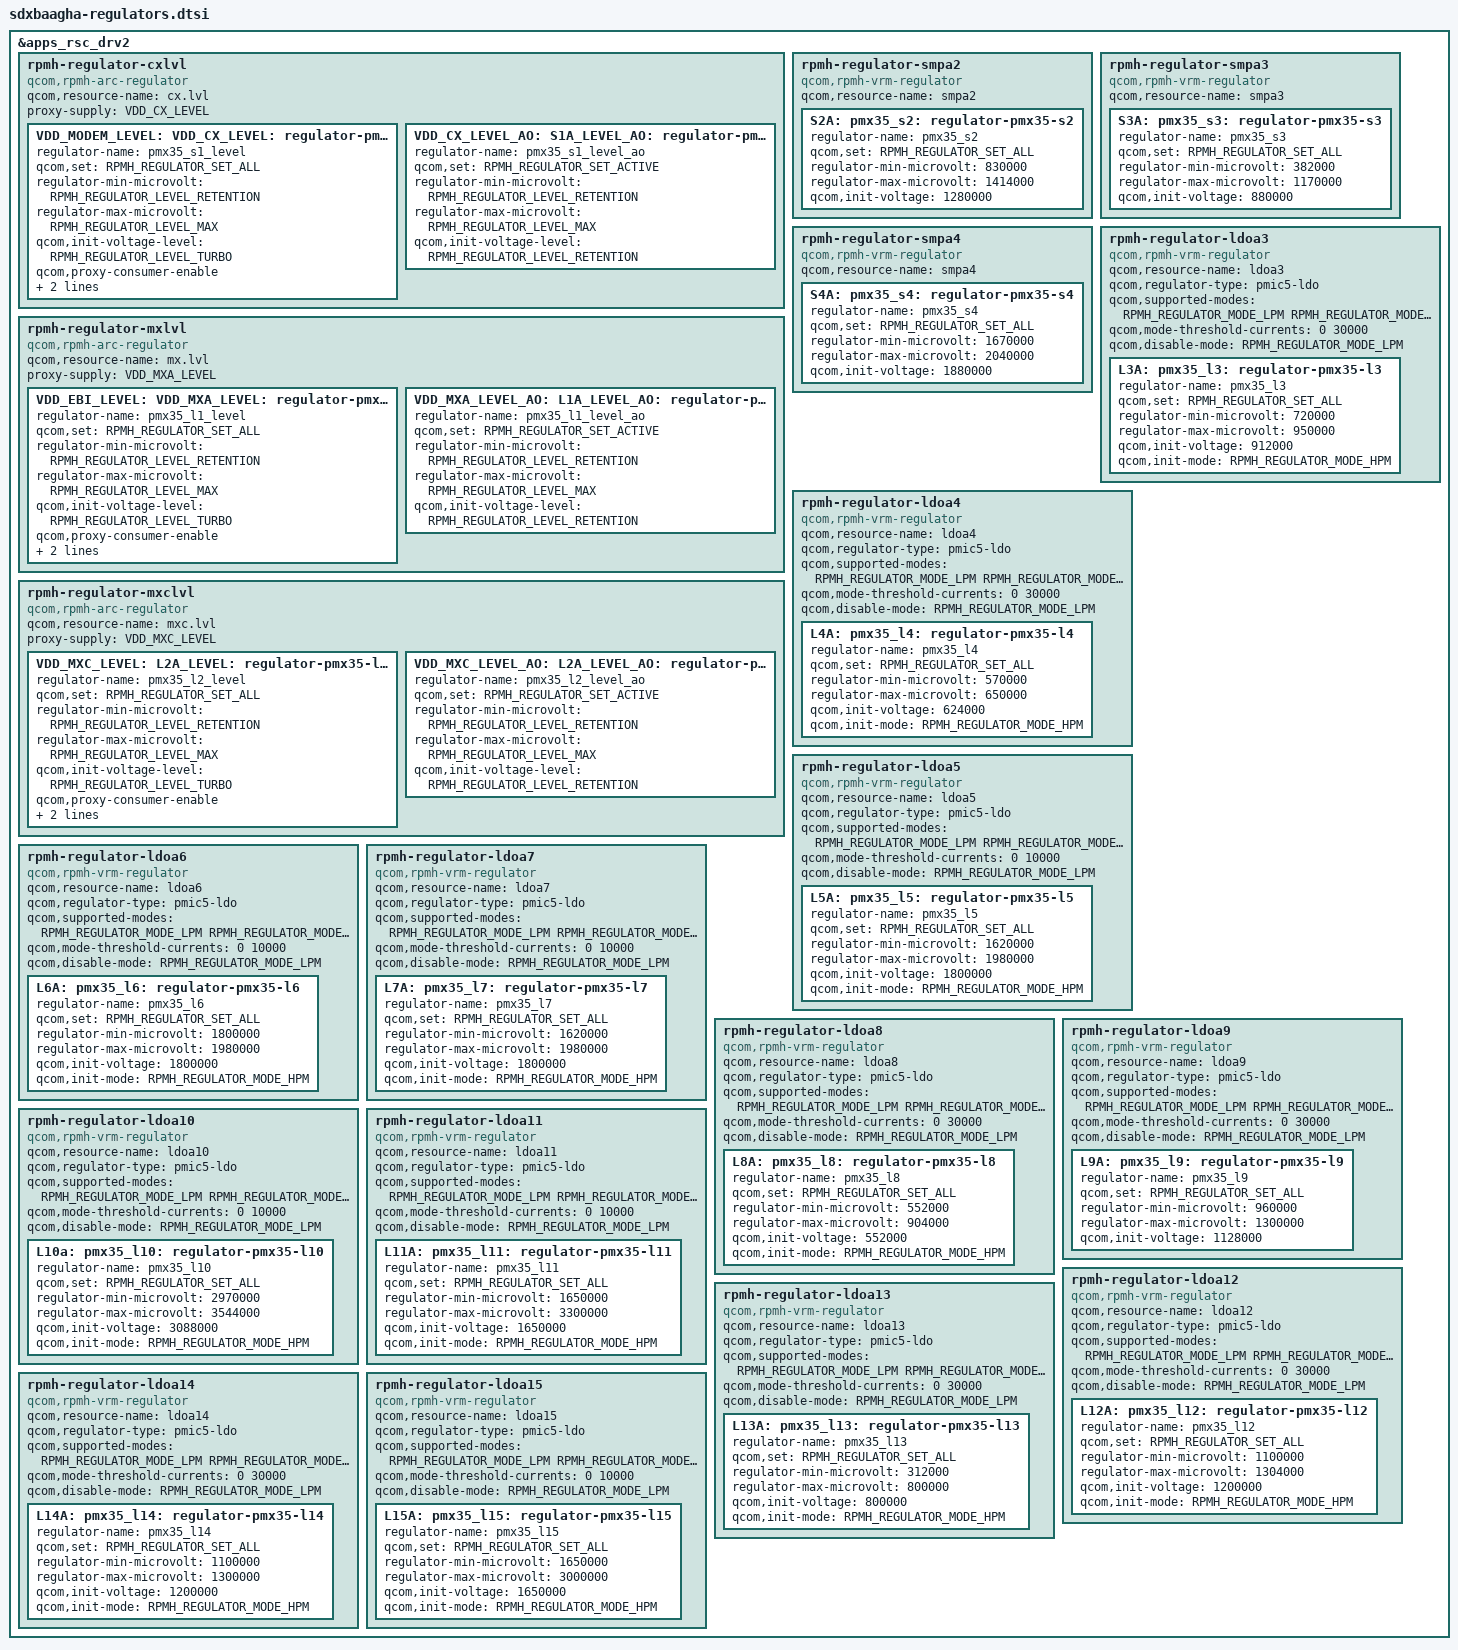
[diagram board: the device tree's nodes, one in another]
#include <dt-bindings/regulator/qcom,rpmh-regulator-levels.h>

&apps_rsc_drv2 {
	rpmh-regulator-cxlvl {
		compatible = "qcom,rpmh-arc-regulator";
		qcom,resource-name = "cx.lvl";
		proxy-supply = <&VDD_CX_LEVEL>;

		VDD_MODEM_LEVEL:
		VDD_CX_LEVEL: S1A_LEVEL:
		pmx35_s1_level: regulator-pmx35-s1-level {
			regulator-name = "pmx35_s1_level";
			qcom,set = <RPMH_REGULATOR_SET_ALL>;
			regulator-min-microvolt =
				<RPMH_REGULATOR_LEVEL_RETENTION>;
			regulator-max-microvolt =
				<RPMH_REGULATOR_LEVEL_MAX>;
			qcom,init-voltage-level =
				<RPMH_REGULATOR_LEVEL_TURBO>;
			qcom,proxy-consumer-enable;
			qcom,proxy-consumer-voltage =
				<RPMH_REGULATOR_LEVEL_TURBO
				 RPMH_REGULATOR_LEVEL_MAX>;

		};

	VDD_CX_LEVEL_AO: S1A_LEVEL_AO:
		pmx35_s1_level_ao: regulator-pmx35-s1-level-ao {
			regulator-name = "pmx35_s1_level_ao";
			qcom,set = <RPMH_REGULATOR_SET_ACTIVE>;
			regulator-min-microvolt =
				<RPMH_REGULATOR_LEVEL_RETENTION>;
			regulator-max-microvolt =
				<RPMH_REGULATOR_LEVEL_MAX>;
			qcom,init-voltage-level =
				<RPMH_REGULATOR_LEVEL_RETENTION>;
		};
	};

	rpmh-regulator-mxlvl {
		compatible = "qcom,rpmh-arc-regulator";
		qcom,resource-name = "mx.lvl";
		proxy-supply = <&VDD_MXA_LEVEL>;

	VDD_EBI_LEVEL: VDD_MXA_LEVEL: L1A_LEVEL:
		pmx35_l1_level: regulator-pmx35-l1-level {
			regulator-name = "pmx35_l1_level";
			qcom,set = <RPMH_REGULATOR_SET_ALL>;
			regulator-min-microvolt =
				<RPMH_REGULATOR_LEVEL_RETENTION>;
			regulator-max-microvolt =
				<RPMH_REGULATOR_LEVEL_MAX>;
			qcom,init-voltage-level =
				<RPMH_REGULATOR_LEVEL_TURBO>;
			qcom,proxy-consumer-enable;
			qcom,proxy-consumer-voltage =
				<RPMH_REGULATOR_LEVEL_TURBO
					RPMH_REGULATOR_LEVEL_MAX>;
		};

		VDD_MXA_LEVEL_AO: L1A_LEVEL_AO:
		pmx35_l1_level_ao: regulator-pmx35-l1-level-ao {
			regulator-name = "pmx35_l1_level_ao";
			qcom,set = <RPMH_REGULATOR_SET_ACTIVE>;
			regulator-min-microvolt =
				<RPMH_REGULATOR_LEVEL_RETENTION>;
			regulator-max-microvolt =
				<RPMH_REGULATOR_LEVEL_MAX>;
			qcom,init-voltage-level =
				<RPMH_REGULATOR_LEVEL_RETENTION>;
		};
	};

	rpmh-regulator-mxclvl {
		compatible = "qcom,rpmh-arc-regulator";
		qcom,resource-name = "mxc.lvl";
		proxy-supply = <&VDD_MXC_LEVEL>;

		VDD_MXC_LEVEL: L2A_LEVEL:
		pmx35_l2_level: regulator-pmx35-l2-level {
			regulator-name = "pmx35_l2_level";
			qcom,set = <RPMH_REGULATOR_SET_ALL>;
			regulator-min-microvolt =
				<RPMH_REGULATOR_LEVEL_RETENTION>;
			regulator-max-microvolt =
				<RPMH_REGULATOR_LEVEL_MAX>;
			qcom,init-voltage-level =
				<RPMH_REGULATOR_LEVEL_TURBO>;
			qcom,proxy-consumer-enable;
			qcom,proxy-consumer-voltage =
				<RPMH_REGULATOR_LEVEL_TURBO
				 RPMH_REGULATOR_LEVEL_MAX>;
		};

		VDD_MXC_LEVEL_AO: L2A_LEVEL_AO:
		pmx35_l2_level_ao: regulator-pmx35-l2-level-ao {
			regulator-name = "pmx35_l2_level_ao";
			qcom,set = <RPMH_REGULATOR_SET_ACTIVE>;
			regulator-min-microvolt =
				<RPMH_REGULATOR_LEVEL_RETENTION>;
			regulator-max-microvolt =
				<RPMH_REGULATOR_LEVEL_MAX>;
			qcom,init-voltage-level =
				<RPMH_REGULATOR_LEVEL_RETENTION>;
		};
	};

	rpmh-regulator-smpa2 {
		compatible = "qcom,rpmh-vrm-regulator";
		qcom,resource-name = "smpa2";

		S2A: pmx35_s2: regulator-pmx35-s2 {
			regulator-name = "pmx35_s2";
			qcom,set = <RPMH_REGULATOR_SET_ALL>;
			regulator-min-microvolt = <830000>;
			regulator-max-microvolt = <1414000>;
			qcom,init-voltage = <1280000>;
		};
	};

	rpmh-regulator-smpa3 {
		compatible = "qcom,rpmh-vrm-regulator";
		qcom,resource-name = "smpa3";

		S3A: pmx35_s3: regulator-pmx35-s3 {
			regulator-name = "pmx35_s3";
			qcom,set = <RPMH_REGULATOR_SET_ALL>;
			regulator-min-microvolt = <382000>;
			regulator-max-microvolt = <1170000>;
			qcom,init-voltage = <880000>;
		};
	};

	rpmh-regulator-smpa4 {
		compatible = "qcom,rpmh-vrm-regulator";
		qcom,resource-name = "smpa4";

		S4A: pmx35_s4: regulator-pmx35-s4 {
			regulator-name = "pmx35_s4";
			qcom,set = <RPMH_REGULATOR_SET_ALL>;
			regulator-min-microvolt = <1670000>;
			regulator-max-microvolt = <2040000>;
			qcom,init-voltage = <1880000>;
		};
	};

	rpmh-regulator-ldoa3 {
		compatible = "qcom,rpmh-vrm-regulator";
		qcom,resource-name = "ldoa3";
		qcom,regulator-type = "pmic5-ldo";
		qcom,supported-modes =
			<RPMH_REGULATOR_MODE_LPM
			 RPMH_REGULATOR_MODE_HPM>;
		qcom,mode-threshold-currents = <0 30000>;
		qcom,disable-mode = <RPMH_REGULATOR_MODE_LPM>;

		L3A: pmx35_l3: regulator-pmx35-l3 {
			regulator-name = "pmx35_l3";
			qcom,set = <RPMH_REGULATOR_SET_ALL>;
			regulator-min-microvolt = <720000>;
			regulator-max-microvolt = <950000>;
			qcom,init-voltage = <912000>;
			qcom,init-mode = <RPMH_REGULATOR_MODE_HPM>;
		};
	};

	rpmh-regulator-ldoa4 {
		compatible = "qcom,rpmh-vrm-regulator";
		qcom,resource-name = "ldoa4";
		qcom,regulator-type = "pmic5-ldo";
		qcom,supported-modes =
			<RPMH_REGULATOR_MODE_LPM
			 RPMH_REGULATOR_MODE_HPM>;
		qcom,mode-threshold-currents = <0 30000>;
		qcom,disable-mode = <RPMH_REGULATOR_MODE_LPM>;

		L4A: pmx35_l4: regulator-pmx35-l4 {
			regulator-name = "pmx35_l4";
			qcom,set = <RPMH_REGULATOR_SET_ALL>;
			regulator-min-microvolt = <570000>;
			regulator-max-microvolt = <650000>;
			qcom,init-voltage = <624000>;
			qcom,init-mode = <RPMH_REGULATOR_MODE_HPM>;
		};
	};

	rpmh-regulator-ldoa5 {
		compatible = "qcom,rpmh-vrm-regulator";
		qcom,resource-name = "ldoa5";
		qcom,regulator-type = "pmic5-ldo";
		qcom,supported-modes =
			<RPMH_REGULATOR_MODE_LPM
			 RPMH_REGULATOR_MODE_HPM>;
		qcom,mode-threshold-currents = <0 10000>;
		qcom,disable-mode = <RPMH_REGULATOR_MODE_LPM>;

		L5A: pmx35_l5: regulator-pmx35-l5 {
			regulator-name = "pmx35_l5";
			qcom,set = <RPMH_REGULATOR_SET_ALL>;
			regulator-min-microvolt = <1620000>;
			regulator-max-microvolt = <1980000>;
			qcom,init-voltage = <1800000>;
			qcom,init-mode = <RPMH_REGULATOR_MODE_HPM>;
		};
	};

	rpmh-regulator-ldoa6 {
		compatible = "qcom,rpmh-vrm-regulator";
		qcom,resource-name = "ldoa6";
		qcom,regulator-type = "pmic5-ldo";
		qcom,supported-modes =
			<RPMH_REGULATOR_MODE_LPM
			 RPMH_REGULATOR_MODE_HPM>;
		qcom,mode-threshold-currents = <0 10000>;
		qcom,disable-mode = <RPMH_REGULATOR_MODE_LPM>;

		L6A: pmx35_l6: regulator-pmx35-l6 {
			regulator-name = "pmx35_l6";
			qcom,set = <RPMH_REGULATOR_SET_ALL>;
			regulator-min-microvolt = <1800000>;
			regulator-max-microvolt = <1980000>;
			qcom,init-voltage = <1800000>;
			qcom,init-mode = <RPMH_REGULATOR_MODE_HPM>;
		};
	};

	rpmh-regulator-ldoa7 {
		compatible = "qcom,rpmh-vrm-regulator";
		qcom,resource-name = "ldoa7";
		qcom,regulator-type = "pmic5-ldo";
		qcom,supported-modes =
			<RPMH_REGULATOR_MODE_LPM
			 RPMH_REGULATOR_MODE_HPM>;
		qcom,mode-threshold-currents = <0 10000>;
		qcom,disable-mode = <RPMH_REGULATOR_MODE_LPM>;

		L7A: pmx35_l7: regulator-pmx35-l7 {
			regulator-name = "pmx35_l7";
			qcom,set = <RPMH_REGULATOR_SET_ALL>;
			regulator-min-microvolt = <1620000>;
			regulator-max-microvolt = <1980000>;
			qcom,init-voltage = <1800000>;
			qcom,init-mode = <RPMH_REGULATOR_MODE_HPM>;
		};
	};

	rpmh-regulator-ldoa8 {
		compatible = "qcom,rpmh-vrm-regulator";
		qcom,resource-name = "ldoa8";
		qcom,regulator-type = "pmic5-ldo";
		qcom,supported-modes =
			<RPMH_REGULATOR_MODE_LPM
			 RPMH_REGULATOR_MODE_HPM>;
		qcom,mode-threshold-currents = <0 30000>;
		qcom,disable-mode = <RPMH_REGULATOR_MODE_LPM>;

		L8A: pmx35_l8: regulator-pmx35-l8 {
			regulator-name = "pmx35_l8";
			qcom,set = <RPMH_REGULATOR_SET_ALL>;
			regulator-min-microvolt = <552000>;
			regulator-max-microvolt = <904000>;
			qcom,init-voltage = <552000>;
			qcom,init-mode = <RPMH_REGULATOR_MODE_HPM>;
		};
	};

	rpmh-regulator-ldoa9 {
		compatible = "qcom,rpmh-vrm-regulator";
		qcom,resource-name = "ldoa9";
		qcom,regulator-type = "pmic5-ldo";
		qcom,supported-modes =
			<RPMH_REGULATOR_MODE_LPM
			 RPMH_REGULATOR_MODE_HPM>;
		qcom,mode-threshold-currents = <0 30000>;
		qcom,disable-mode = <RPMH_REGULATOR_MODE_LPM>;

		L9A: pmx35_l9: regulator-pmx35-l9 {
			regulator-name = "pmx35_l9";
			qcom,set = <RPMH_REGULATOR_SET_ALL>;
			regulator-min-microvolt = <960000>;
			regulator-max-microvolt = <1300000>;
			qcom,init-voltage = <1128000>;
		};
	};

	rpmh-regulator-ldoa10 {
		compatible = "qcom,rpmh-vrm-regulator";
		qcom,resource-name = "ldoa10";
		qcom,regulator-type = "pmic5-ldo";
		qcom,supported-modes =
			<RPMH_REGULATOR_MODE_LPM
			 RPMH_REGULATOR_MODE_HPM>;
		qcom,mode-threshold-currents = <0 10000>;
		qcom,disable-mode = <RPMH_REGULATOR_MODE_LPM>;

		L10a: pmx35_l10: regulator-pmx35-l10 {
			regulator-name = "pmx35_l10";
			qcom,set = <RPMH_REGULATOR_SET_ALL>;
			regulator-min-microvolt = <2970000>;
			regulator-max-microvolt = <3544000>;
			qcom,init-voltage = <3088000>;
			qcom,init-mode = <RPMH_REGULATOR_MODE_HPM>;
		};
	};

	rpmh-regulator-ldoa11 {
		compatible = "qcom,rpmh-vrm-regulator";
		qcom,resource-name = "ldoa11";
		qcom,regulator-type = "pmic5-ldo";
		qcom,supported-modes =
			<RPMH_REGULATOR_MODE_LPM
			 RPMH_REGULATOR_MODE_HPM>;
		qcom,mode-threshold-currents = <0 10000>;
		qcom,disable-mode = <RPMH_REGULATOR_MODE_LPM>;

		L11A: pmx35_l11: regulator-pmx35-l11 {
			regulator-name = "pmx35_l11";
			qcom,set = <RPMH_REGULATOR_SET_ALL>;
			regulator-min-microvolt = <1650000>;
			regulator-max-microvolt = <3300000>;
			qcom,init-voltage = <1650000>;
			qcom,init-mode = <RPMH_REGULATOR_MODE_HPM>;
		};
	};

	rpmh-regulator-ldoa12 {
		compatible = "qcom,rpmh-vrm-regulator";
		qcom,resource-name = "ldoa12";
		qcom,regulator-type = "pmic5-ldo";
		qcom,supported-modes =
			<RPMH_REGULATOR_MODE_LPM
			 RPMH_REGULATOR_MODE_HPM>;
		qcom,mode-threshold-currents = <0 30000>;
		qcom,disable-mode = <RPMH_REGULATOR_MODE_LPM>;

		L12A: pmx35_l12: regulator-pmx35-l12 {
			regulator-name = "pmx35_l12";
			qcom,set = <RPMH_REGULATOR_SET_ALL>;
			regulator-min-microvolt = <1100000>;
			regulator-max-microvolt = <1304000>;
			qcom,init-voltage = <1200000>;
			qcom,init-mode = <RPMH_REGULATOR_MODE_HPM>;
		};
	};

	rpmh-regulator-ldoa13 {
		compatible = "qcom,rpmh-vrm-regulator";
		qcom,resource-name = "ldoa13";
		qcom,regulator-type = "pmic5-ldo";
		qcom,supported-modes =
			<RPMH_REGULATOR_MODE_LPM
			 RPMH_REGULATOR_MODE_HPM>;
		qcom,mode-threshold-currents = <0 30000>;
		qcom,disable-mode = <RPMH_REGULATOR_MODE_LPM>;

		L13A: pmx35_l13: regulator-pmx35-l13 {
			regulator-name = "pmx35_l13";
			qcom,set = <RPMH_REGULATOR_SET_ALL>;
			regulator-min-microvolt = <312000>;
			regulator-max-microvolt = <800000>;
			qcom,init-voltage = <800000>;
			qcom,init-mode = <RPMH_REGULATOR_MODE_HPM>;
		};
	};

	rpmh-regulator-ldoa14 {
		compatible = "qcom,rpmh-vrm-regulator";
		qcom,resource-name = "ldoa14";
		qcom,regulator-type = "pmic5-ldo";
		qcom,supported-modes =
			<RPMH_REGULATOR_MODE_LPM
			 RPMH_REGULATOR_MODE_HPM>;
		qcom,mode-threshold-currents = <0 30000>;
		qcom,disable-mode = <RPMH_REGULATOR_MODE_LPM>;

		L14A: pmx35_l14: regulator-pmx35-l14 {
			regulator-name = "pmx35_l14";
			qcom,set = <RPMH_REGULATOR_SET_ALL>;
			regulator-min-microvolt = <1100000>;
			regulator-max-microvolt = <1300000>;
			qcom,init-voltage = <1200000>;
			qcom,init-mode = <RPMH_REGULATOR_MODE_HPM>;
		};
	};

	rpmh-regulator-ldoa15 {
		compatible = "qcom,rpmh-vrm-regulator";
		qcom,resource-name = "ldoa15";
		qcom,regulator-type = "pmic5-ldo";
		qcom,supported-modes =
			<RPMH_REGULATOR_MODE_LPM
			 RPMH_REGULATOR_MODE_HPM>;
		qcom,mode-threshold-currents = <0 10000>;
		qcom,disable-mode = <RPMH_REGULATOR_MODE_LPM>;

		L15A: pmx35_l15: regulator-pmx35-l15 {
			regulator-name = "pmx35_l15";
			qcom,set = <RPMH_REGULATOR_SET_ALL>;
			regulator-min-microvolt = <1650000>;
			regulator-max-microvolt = <3000000>;
			qcom,init-voltage = <1650000>;
			qcom,init-mode = <RPMH_REGULATOR_MODE_HPM>;
		};
	};
};
